# CH641 register map
Vendor: WCH Ltd.; File version: 1.0
Registers are 32-bit, read-write, reset 0x0 unless marked. A register's access mark holds for its fields unless they carry their own. Offsets are from the block's base; [hi:lo] are bit positions.

## TIM1 — Advanced timer
Base 0x40012C00
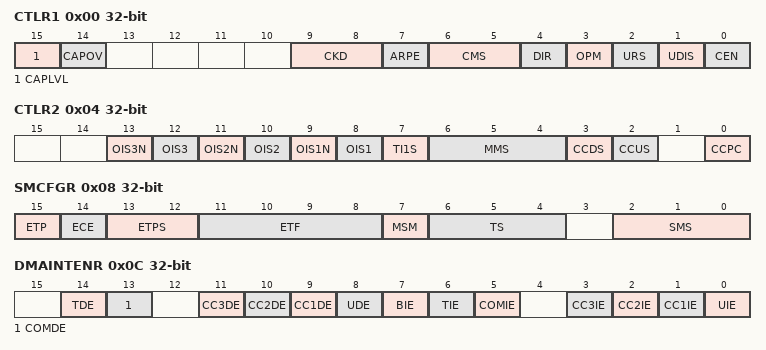
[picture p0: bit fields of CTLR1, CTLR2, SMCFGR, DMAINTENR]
0x00 CTLR1 — control register 1
  [15] CAPLVL — Timer capture level indication enable
  [14] CAPOV — Timer capture value configuration enable
  [9:8] CKD — Clock division
  [7] ARPE — Auto-reload preload enable
  [6:5] CMS — Center-aligned mode selection
  [4] DIR — Direction
  [3] OPM — One-pulse mode
  [2] URS — Update request source
  [1] UDIS — Update disable
  [0] CEN — Counter enable
0x04 CTLR2 — control register 2
  [13] OIS3N — Output Idle state 3
  [12] OIS3 — Output Idle state 3
  [11] OIS2N — Output Idle state 2
  [10] OIS2 — Output Idle state 2
  [9] OIS1N — Output Idle state 1
  [8] OIS1 — Output Idle state 1
  [7] TI1S — TI1 selection
  [6:4] MMS — Master mode selection
  [3] CCDS — Capture/compare DMA selection
  [2] CCUS — Capture/compare control update selection
  [0] CCPC — Capture/compare preloaded control
0x08 SMCFGR access per field — slave mode control register
  [15] ETP ro — External trigger polarity
  [14] ECE rw — External clock enable
  [13:12] ETPS rw — External trigger prescaler
  [11:8] ETF rw — External trigger filter
  [7] MSM rw — Master/Slave mode
  [6:4] TS rw — Trigger selection
  [2:0] SMS rw — Slave mode selection
0x0C DMAINTENR — DMA/Interrupt enable register
  [14] TDE — Trigger DMA request enable
  [13] COMDE — COM DMA request enable
  [11] CC3DE — Capture/Compare 3 DMA request enable
  [10] CC2DE — Capture/Compare 2 DMA request enable
  [9] CC1DE — Capture/Compare 1 DMA request enable
  [8] UDE — Update DMA request enable
  [7] BIE — Break interrupt enable
  [6] TIE — Trigger interrupt enable
  [5] COMIE — COM interrupt enable
  [3] CC3IE — Capture/Compare 3 interrupt enable
  [2] CC2IE — Capture/Compare 2 interrupt enable
  [1] CC1IE — Capture/Compare 1 interrupt enable
  [0] UIE — Update interrupt enable
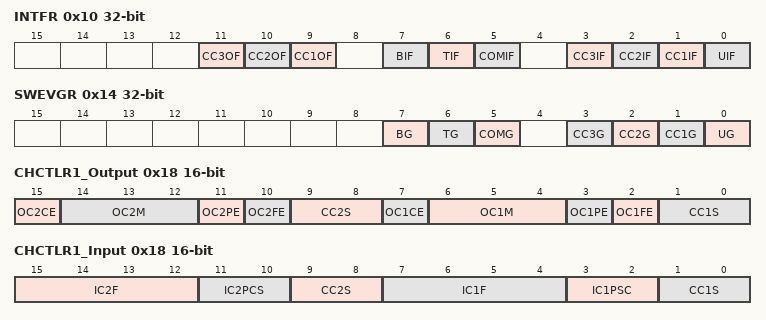
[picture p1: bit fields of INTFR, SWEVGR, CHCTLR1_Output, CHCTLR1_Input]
0x10 INTFR — status register
  [11] CC3OF — Capture/Compare 3 overcapture flag
  [10] CC2OF — Capture/compare 2 overcapture flag
  [9] CC1OF — Capture/Compare 1 overcapture flag
  [7] BIF — Break interrupt flag
  [6] TIF — Trigger interrupt flag
  [5] COMIF — COM interrupt flag
  [3] CC3IF — Capture/Compare 3 interrupt flag
  [2] CC2IF — Capture/Compare 2 interrupt flag
  [1] CC1IF — Capture/compare 1 interrupt flag
  [0] UIF — Update interrupt flag
0x14 SWEVGR wo — event generation register
  [7] BG — Break generation
  [6] TG — Trigger generation
  [5] COMG — Capture/Compare control update generation
  [3] CC3G — Capture/compare 3 generation
  [2] CC2G — Capture/compare 2 generation
  [1] CC1G — Capture/compare 1 generation
  [0] UG — Update generation
0x18 CHCTLR1_Output 16-bit — capture/compare mode register (output mode)
  [15] OC2CE — Output Compare 2 clear enable
  [14:12] OC2M — Output Compare 2 mode
  [11] OC2PE — Output Compare 2 preload enable
  [10] OC2FE — Output Compare 2 fast enable
  [9:8] CC2S — Capture/Compare 2 selection
  [7] OC1CE — Output Compare 1 clear enable
  [6:4] OC1M — Output Compare 1 mode
  [3] OC1PE — Output Compare 1 preload enable
  [2] OC1FE — Output Compare 1 fast enable
  [1:0] CC1S — Capture/Compare 1 selection
0x18 CHCTLR1_Input 16-bit (alternate view of CHCTLR1_Output) — capture/compare mode register 1 (input mode)
  [15:12] IC2F — Input capture 2 filter
  [11:10] IC2PCS — Input capture 2 prescaler
  [9:8] CC2S — Capture/Compare 2 selection
  [7:4] IC1F — Input capture 1 filter
  [3:2] IC1PSC — Input capture 1 prescaler
  [1:0] CC1S — Capture/Compare 1 selection
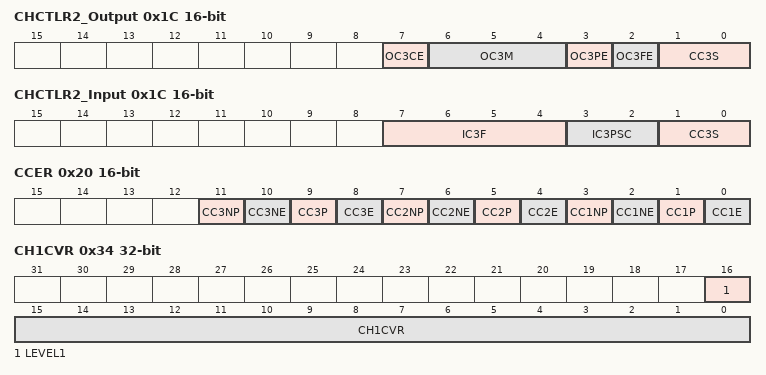
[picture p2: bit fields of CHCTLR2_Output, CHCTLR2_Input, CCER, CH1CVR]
0x1C CHCTLR2_Output 16-bit — capture/compare mode register (output mode)
  [7] OC3CE — Output compare 3 clear enable
  [6:4] OC3M — Output compare 3 mode
  [3] OC3PE — Output compare 3 preload enable
  [2] OC3FE — Output compare 3 fast enable
  [1:0] CC3S — Capture/Compare 3 selection
0x1C CHCTLR2_Input 16-bit (alternate view of CHCTLR2_Output) — capture/compare mode register 2 (input mode)
  [7:4] IC3F — Input capture 3 filter
  [3:2] IC3PSC — Input capture 3 prescaler
  [1:0] CC3S — Capture/compare 3 selection
0x20 CCER 16-bit — capture/compare enable register
  [11] CC3NP — Capture/Compare 3 output Polarity
  [10] CC3NE — Capture/Compare 3 complementary output enable
  [9] CC3P — Capture/Compare 3 output Polarity
  [8] CC3E — Capture/Compare 3 output enable
  [7] CC2NP — Capture/Compare 2 output Polarity
  [6] CC2NE — Capture/Compare 2 complementary output enable
  [5] CC2P — Capture/Compare 2 output Polarity
  [4] CC2E — Capture/Compare 2 output enable
  [3] CC1NP — Capture/Compare 1 output Polarity
  [2] CC1NE — Capture/Compare 1 complementary output enable
  [1] CC1P — Capture/Compare 1 output Polarity
  [0] CC1E — Capture/Compare 1 output enable
0x24 CNT 16-bit — counter
  [15:0] CNT — counter value
0x28 PSC 16-bit — prescaler
  [15:0] PSC — Prescaler value
0x2C ATRLR — auto-reload register
  [15:0] ATRLR — Auto-reload value
0x30 RPTCR 16-bit — repetition counter register
  [7:0] RPTCR — Repetition counter value
0x34 CH1CVR — capture/compare register 1
  [16] LEVEL1 — Level indicating bit
  [15:0] CH1CVR — Capture/Compare 1 value
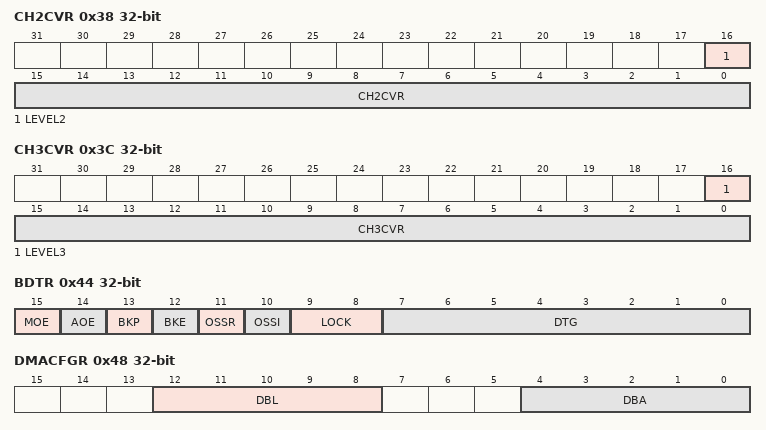
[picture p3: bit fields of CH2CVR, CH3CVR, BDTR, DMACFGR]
0x38 CH2CVR — capture/compare register 2
  [16] LEVEL2 — Level indicating bit
  [15:0] CH2CVR — Capture/Compare 2 value
0x3C CH3CVR — capture/compare register 3
  [16] LEVEL3 — Level indicating bit
  [15:0] CH3CVR — Capture/Compare value
0x44 BDTR — break and dead-time register
  [15] MOE — Main output enable
  [14] AOE — Automatic output enable
  [13] BKP — Break polarity
  [12] BKE — Break enable
  [11] OSSR — Off-state selection for Run mode
  [10] OSSI — Off-state selection for Idle mode
  [9:8] LOCK — Lock configuration
  [7:0] DTG — Dead-time generator setup
0x48 DMACFGR — DMA control register
  [12:8] DBL — DMA burst length
  [4:0] DBA — DMA base address
0x4C DMAADR — DMA address for full transfer
  [15:0] DMAADR — DMA register for burst accesses
